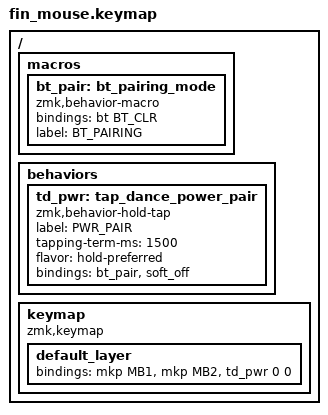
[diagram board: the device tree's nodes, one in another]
#include <behaviors.dtsi>
#include <dt-bindings/zmk/keys.h>
#include <dt-bindings/zmk/bt.h>
#include <dt-bindings/zmk/mouse.h>
#include <dt-bindings/zmk/outputs.h>

/ {
    /* [매크로] 페어링 모드 진입 (기존 연결 끊고 대기) */
    macros {
        bt_pair: bt_pairing_mode {
            compatible = "zmk,behavior-macro";
            #binding-cells = <0>;
            bindings = <&bt BT_CLR>;
            label = "BT_PAIRING";
        };
    };

    /* [동작] 짧게=전원(Sleep), 길게=페어링 초기화 */
    behaviors {
        td_pwr: tap_dance_power_pair {
            compatible = "zmk,behavior-hold-tap";
            label = "PWR_PAIR";
            #binding-cells = <2>;
            tapping-term-ms = <1500>;    /* 1.5초 꾹 누르면 페어링 */
            flavor = "hold-preferred";
            bindings = <&bt_pair>, <&soft_off>; /* <길게>, <짧게> */
        };
    };

    keymap {
        compatible = "zmk,keymap";

        default_layer {
            bindings = <
                &mkp MB1      /* 0번: 좌클릭 (P1.13) */
                &mkp MB2      /* 1번: 우클릭 (P1.14) */
                &td_pwr 0 0   /* 2번: 블루투스/전원 (P1.12) */
            >;
        };
    };
};
